# SIM3L164_C register map
File version: 1
CPU: 
Registers are 32-bit, read-write, reset 0x0 unless marked. A register's access mark holds for its fields unless they carry their own. Offsets are from the block's base; [hi:lo] are bit positions; {n}, {i} and the like mark numbered series.

## FLASHCTRL_0
Base 0x4002E000
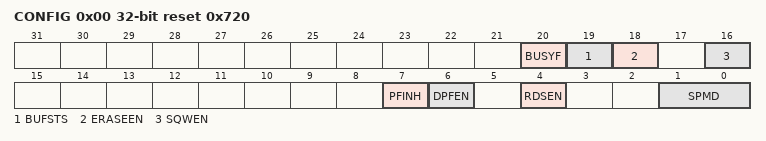
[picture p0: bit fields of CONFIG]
0x00 CONFIG reset 0x720 — Controller Configuration
  [20] BUSYF ro — Flash Operation Busy Flag.
    0=NOT_SET (The flash interface is not busy.); 1=SET (The flash interface is busy with an operation.)
  [19] BUFSTS ro — Flash Buffer Status.
    0=EMPTY (The flash controller write data buffer is empty.); 1=FULL (The flash controller write data buffer is full.)
  [18] ERASEEN — Flash Page Erase Enable.
    0=DISABLED (Writes to the WRDATA field will initiate a write to flash at the address in the WRADDR field.); 1=ENABLED (Writes to the WRDATA field will initiate an erase of the flash page containing the address in the WRADDR field.)
  [16] SQWEN — Flash Write Sequence Enable.
    0=DISABLED (Disable sequential write mode.); 1=ENABLED (Enable sequential write mode.)
  [7] PFINH — Prefetch Inhibit.
    0=INACTIVE (Any reads from flash are prefetched until the prefetch buffer is full.); 1=ACTIVE (Inhibit the prefetch engine.)
  [6] DPFEN — Data Prefetch Enable.
    0=DISABLED (Data accesses are excluded from the prefetch buffer.); 1=ENABLED (Data accesses are included in the prefetch buffer.)
  [4] RDSEN — Read Store Mode Enable.
    0=DISABLED (Disable read store mode.); 1=ENABLED (Enable read store mode.)
  [1:0] SPMD — Flash Speed Mode.
    {v}=MODE{v} (Read and write the flash at speed mode {v}.) (v=0..3)
0xA0 WRADDR — Flash Write Address
  [31:0] WRADDR — Flash Write Address.
0xB0 WRDATA — Flash Write Data
  [31:0] WRDATA wo — Flash Write Data.
0xC0 KEY — Flash Modification Key
  [7:0] KEY — Flash Key.
    90=MULTI_LOCK; 165=INITIAL_UNLOCK; 241=SINGLE_UNLOCK; 242=MULTI_UNLOCK
0xD0 TCONTROL reset 0x3005C — Flash Timing Control
  [6] FLRTMD — Flash Read Timing Mode.
    0=SLOW (Configure the flash read controller for AHB clocks below 12 MHz.); 1=FAST (Configure the flash read controller for AHB clocks above 12 MHz.)

## LDO_0
Base 0x40039000
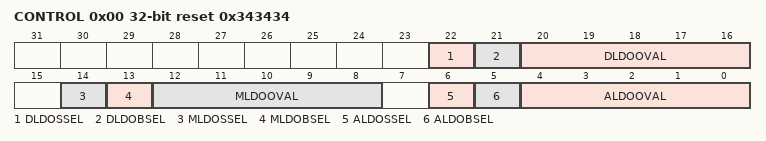
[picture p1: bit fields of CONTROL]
0x00 CONTROL reset 0x343434
  [22] DLDOSSEL — Digital LDO Source Select.
    0=VBAT (Select the VBAT pin as the input voltage to the digital LDO.); 1=DCDC (Select the output of the DC-DC converter as the input voltage to the digital LDO.)
  [21] DLDOBSEL — Digital LDO Bias Select.
    0=LOW (Select a low bias for the digital LDO.); 1=HIGH (Select a high bias for the digital LDO.)
  [20:16] DLDOOVAL — Digital LDO Output Value Select.
  [14] MLDOSSEL — Memory LDO Source Select.
    0=VBAT (Select the VBAT pin as the input voltage to the memory LDO.); 1=DCDC (Select the output of the DC-DC converter as the input voltage to the memory LDO.)
  [13] MLDOBSEL — Memory LDO Bias Select.
    0=LOW (Select a low bias for the memory LDO.); 1=HIGH (Select a high bias for the memory LDO.)
  [12:8] MLDOOVAL — Memory LDO Output Value Select.
  [6] ALDOSSEL — Analog LDO Source Select.
    0=VBAT (Select the VBAT pin as the input voltage to the analog LDO.); 1=DCDC (Select the output of the DC-DC converter as the input voltage to the analog LDO.)
  [5] ALDOBSEL — Analog LDO Bias Select.
    0=LOW (Select a low bias for the analog LDO.); 1=HIGH (Select a high bias for the analog LDO.)
  [4:0] ALDOOVAL — Analog LDO Output Value Select.

## PLL_0
Base 0x4003B000
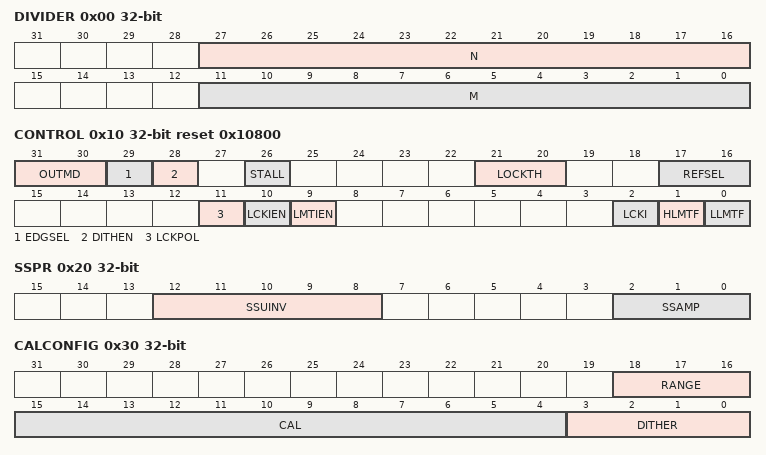
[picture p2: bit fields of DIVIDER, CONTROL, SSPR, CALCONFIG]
0x00 DIVIDER — Reference Divider Setting
  [27:16] N — N Divider Value.
  [11:0] M — M Divider Value.
0x10 CONTROL reset 0x10800 — Module Control
  [31:30] OUTMD — PLL Output Mode.
    0=OFF (DCO output is off.); 1=DCO (DCO output is in Free-Running DCO mode.); 2=FLL (DCO output is in frequency-lock mode (reference source required).); 3=PLL (DCO output is in phase-lock mode (reference source required).)
  [29] EDGSEL — Edge Lock Select.
    0=FALLING_EDGE (Lock DCO output frequency to the falling edge of the reference frequency.); 1=RISING_EDGE (Lock DCO output frequency to the rising edge of the reference frequency.)
  [28] DITHEN — Dithering Enable.
    0=DISABLED (Automatic DCO output dithering disabled.); 1=ENABLED (Automatic DCO output dithering enabled.)
  [26] STALL — DCO Output Updates Stall.
    0=DISABLED (In phase-lock and frequency-lock modes, spectrum spreading, and dithering operate normally, if enabled.); 1=ENABLED (In phase-lock and frequency-lock modes, spectrum spreading, and dithering are prevented from updating the output of the DCO.)
  [21:20] LOCKTH — Lock Threshold Control.
  [17:16] REFSEL — Reference Clock Selection Control.
    0=RTC0TCLK (PLL reference clock (FREF) is the RTC0 oscillator (RTC0TCLK).); 1=LPOSC0DIV (PLL reference clock (FREF) is the divided Low Power Oscillator (LPOSC0).); 2=EXTOSC0 (PLL reference clock (FREF) is the external oscillator output (EXTOSC0).)
  [11] LCKPOL — Lock Interrupt Polarity.
    0=ACTIVE_LOW (The lock state PLL interrupt will occur when LCKI is 0.); 1=ACTIVE_HIGH (The lock state PLL interrupt will occur when LCKI is 1.)
  [10] LCKIEN — Locked Interrupt Enable.
    0=DISABLED (The PLL locking does not cause an interrupt); 1=ENABLED (An interrupt is generated if LCKI matches the state selected by LCKPOL.)
  [9] LMTIEN — Limit Interrupt Enable.
    0=DISABLED (Saturation (high and low) interrupt disabled.); 1=ENABLED (Saturation (high and low) interrupt enabled.)
  [2] LCKI ro — Phase-Lock and Frequency-Lock Locked Interrupt Flag.
    0=NOT_SET (DCO is disabled or not locked.); 1=SET (DCO is enabled and locked.)
  [1] HLMTF ro — CAL Saturation (High) Flag.
    0=NOT_SET (DCO period is not saturated high.); 1=SET (DCO period is saturated high.)
  [0] LLMTF ro — CAL Saturation (Low) Flag.
    0=NOT_SET (DCO period is not saturated low.); 1=SET (DCO period is saturated low.)
0x20 SSPR — Spectrum Spreading Control
  [12:8] SSUINV — Spectrum Spreading Update Interval.
  [2:0] SSAMP — Spectrum Spreading Amplitude.
    0=DISABLED (Disable Spectrum Spreading.); 1=SETTING1 (Spectrum Spreading set to approximately +/- 0.1% of TDCO.); 2=SETTING2 (Spectrum Spreading set to approximately +/- 0.2% of TDCO.); 3=SETTING3 (Spectrum Spreading set to approximately +/- 0.4% of TDCO.); 4=SETTING4 (Spectrum Spreading set to approximately +/- 0.8% of TDCO.); 5=SETTING5 (Spectrum Spreading set to approximately +/- 1.6% of TDCO.)
0x30 CALCONFIG — Calibration Configuration
  [18:16] RANGE — DCO Range.
    0=DCO operates from 23 to 37 MHz; 1=DCO operates from 33 to 50 MHz; 2=DCO operates from 45 to 50 MHz
  [15:4] CAL — DCO Calibration Value.
  [3:0] DITHER — DCO Dither Setting.
